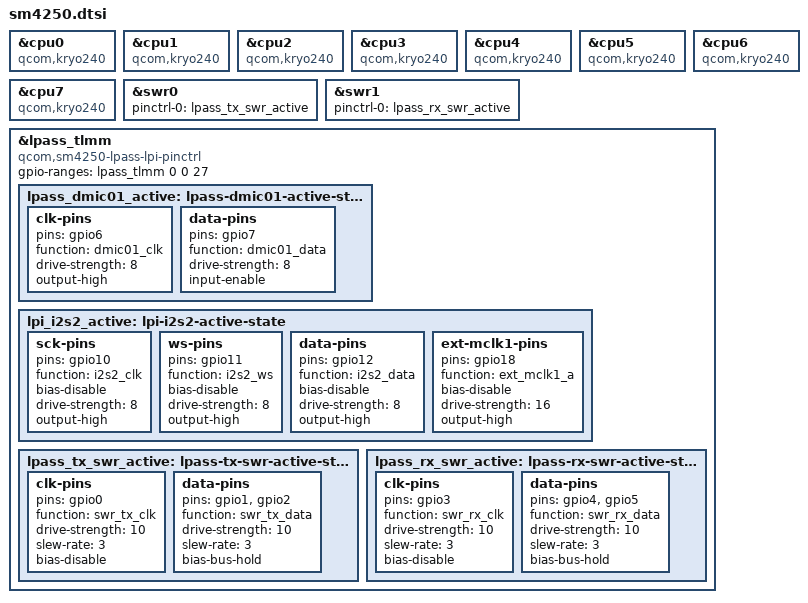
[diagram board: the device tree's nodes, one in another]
// SPDX-License-Identifier: (GPL-2.0+ OR BSD-3-Clause)
/*
 * Copyright (c) 2021, Iskren Chernev <iskren.chernev@gmail.com>
 */

#include "sm6115.dtsi"

&cpu0 {
	compatible = "qcom,kryo240";
};

&cpu1 {
	compatible = "qcom,kryo240";
};

&cpu2 {
	compatible = "qcom,kryo240";
};

&cpu3 {
	compatible = "qcom,kryo240";
};

&cpu4 {
	compatible = "qcom,kryo240";
};

&cpu5 {
	compatible = "qcom,kryo240";
};

&cpu6 {
	compatible = "qcom,kryo240";
};

&cpu7 {
	compatible = "qcom,kryo240";
};

&swr0 {
	pinctrl-0 = <&lpass_tx_swr_active>;
	pinctrl-names = "default";
};

&swr1 {
	pinctrl-0 = <&lpass_rx_swr_active>;
	pinctrl-names = "default";
};

&lpass_tlmm {
	compatible = "qcom,sm4250-lpass-lpi-pinctrl";
	gpio-ranges = <&lpass_tlmm 0 0 27>;

	lpass_dmic01_active: lpass-dmic01-active-state {
		clk-pins {
			pins = "gpio6";
			function = "dmic01_clk";
			drive-strength = <8>;
			output-high;
		};

		data-pins {
			pins = "gpio7";
			function = "dmic01_data";
			drive-strength = <8>;
			input-enable;
		};
	};

	lpi_i2s2_active: lpi-i2s2-active-state {
		sck-pins {
			pins = "gpio10";
			function = "i2s2_clk";
			bias-disable;
			drive-strength = <8>;
			output-high;
		};

		ws-pins {
			pins = "gpio11";
			function = "i2s2_ws";
			bias-disable;
			drive-strength = <8>;
			output-high;
		};

		data-pins {
			pins = "gpio12";
			function = "i2s2_data";
			bias-disable;
			drive-strength = <8>;
			output-high;
		};

		ext-mclk1-pins {
			pins = "gpio18";
			function = "ext_mclk1_a";
			bias-disable;
			drive-strength = <16>;
			output-high;
		};
	};

	lpass_tx_swr_active: lpass-tx-swr-active-state {
		clk-pins {
			pins = "gpio0";
			function = "swr_tx_clk";
			drive-strength = <10>;
			slew-rate = <3>;
			bias-disable;
		};

		data-pins {
			pins = "gpio1", "gpio2";
			function = "swr_tx_data";
			drive-strength = <10>;
			slew-rate = <3>;
			bias-bus-hold;
		};
	};

	lpass_rx_swr_active: lpass-rx-swr-active-state {
		clk-pins {
			pins = "gpio3";
			function = "swr_rx_clk";
			drive-strength = <10>;
			slew-rate = <3>;
			bias-disable;
		};

		data-pins {
			pins = "gpio4", "gpio5";
			function = "swr_rx_data";
			drive-strength = <10>;
			slew-rate = <3>;
			bias-bus-hold;
		};
	};
};
